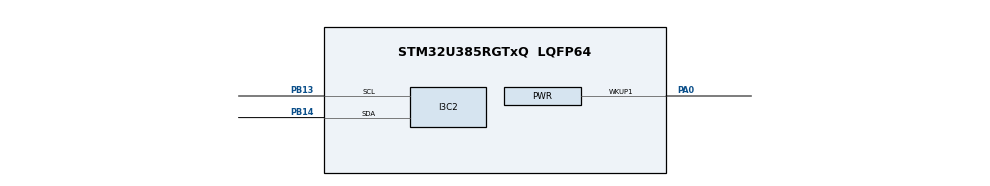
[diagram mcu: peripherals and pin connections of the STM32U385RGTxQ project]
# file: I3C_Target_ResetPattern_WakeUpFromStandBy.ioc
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CORTEX_M33_NS.userName=CORTEX_M33
I3C2.IBIPayloadSize=HAL_I3C_PAYLOAD_EMPTY
I3C2.Identifier=0xC6
I3C2.MIPIIdentifier=DEVICE_ID
I3C2.MaxReadDataSize=0xFF
I3C2.MaxWriteDataSize=0xFF
I3C2.Register1=0x000000f8
I3C2.T_BusAvailableDuration=10000
I3C2.hexBusAvailableDuration=0xf8
Mcu.Family=STM32U3
Mcu.Name=STM32U385RGTxQ
Mcu.Package=LQFP64
Mcu.UserConstants=DEVICE_ID,0x01
NVIC.I3C2_ER_IRQn=true\:0\:0\:false\:false\:true\:true\:true\:true
NVIC.I3C2_EV_IRQn=true\:0\:0\:false\:false\:true\:true\:true\:true
NVIC.PriorityGroup=NVIC_PRIORITYGROUP_4
PA0.Mode=WakeUp1
PA0.Signal=PWR_WKUP1
PB13.Mode=Target
PB13.Signal=I3C2_SCL
PB14.Mode=Target
PB14.Signal=I3C2_SDA
PWR.pwrPrivilege=PWR_PRIVILEGE_NO
ProjectManager.HeapSize=0x200
ProjectManager.StackSize=0x400
ProjectManager.TargetToolchain=EWARM V9.20
RCC.ADCFreq_Value=96000000
RCC.AHBFreq_Value=96000000
RCC.APB1Freq_Value=96000000
RCC.APB1TimFreq_Value=96000000
RCC.APB2Freq_Value=96000000
RCC.APB2TimFreq_Value=96000000
RCC.APB3Freq_Value=96000000
RCC.CortexFreq_Value=12000000
RCC.HCLKFreq_Value=96000000
RCC.HSE_VALUE=16000000
RCC.HSI48_VALUE=48000000
RCC.HSI_VALUE=16000000
RCC.I3C2CLockSelection=RCC_I3C2CLKSOURCE_MSIK
RCC.LSE_VALUE=32768
RCC.LSIDIV_VALUE=32000
RCC.MSISDIV=RCC_MSI_DIV1
RCC.SYSCLKFreq_VALUE=96000000
RCC.USBFreq_Value=96000000
VP_ICACHE_VS_ICACHE.Mode=DirectMappedCache
VP_MEMORYMAP_VS_MEMORYMAP.Mode=CurAppReg
VP_PWR_VS_DBSignals.Mode=DisableDeadBatterySignals
VP_PWR_VS_LPOM.Mode=PowerOptimisation
VP_PWR_VS_SECSignals.Mode=Security/Privilege
board=custom

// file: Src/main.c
/* USER CODE BEGIN Header */
/**
  ******************************************************************************
  * @file           : I3C/I3C_Target_ResetPattern_WakeUpFromStandBy/Src/main.c
  * @brief          : This sample code shows how to use STM32U3xx I3C HAL API
  *                   as Target to detect reset pattern and wake up from Standby mode.
  *                   The communication is done using 2 boards.
  ******************************************************************************
  * @attention
  *
  * Copyright (c) 2024 STMicroelectronics.
  * All rights reserved.
  *
  * This software is licensed under terms that can be found in the LICENSE file
  * in the root directory of this software component.
  * If no LICENSE file comes with this software, it is provided AS-IS.
  *
  ******************************************************************************
  */
/* USER CODE END Header */
#include "main.h"

I3C_HandleTypeDef hi3c2;

/* USER CODE BEGIN PV */
/* Variable used to catch completion of Dynamic address assignment procedure */
__IO uint8_t ubDynamicAddressCplt = 0;

/* Variable used to catch wake up from stand by */
__IO uint8_t ubWakeUpFromStandBy = 0;
/* USER CODE END PV */

void SystemClock_Config(void);
static void MX_GPIO_Init(void);
static void MX_I3C2_Init(void);
static void MX_ICACHE_Init(void);

int main(void)
{

  /* MCU Configuration--------------------------------------------------------*/

  /* Reset of all peripherals, Initializes the Flash interface and the Systick. */
  HAL_Init();

  /* USER CODE BEGIN Init */
  /* Check StandBy flag */
  if (__HAL_PWR_GET_FLAG(PWR_FLAG_SBF) == 1U)
  {
    /* Clear standby flag */
    __HAL_PWR_CLEAR_FLAG(PWR_FLAG_SBF);

    /* Check and clear wake up flag */
    if (HAL_PWR_GetClearWakeupSource() == PWR_WAKEUP_LINE10)
    {
      /* Wake up from STANDBY */
      ubWakeUpFromStandBy = 1U;
    }
    else
    {
      Error_Handler();
    }
  }
  /* USER CODE END Init */

  /* Configure the system clock */
  SystemClock_Config();

  /* Initialize all configured peripherals */
  MX_GPIO_Init();
  MX_I3C2_Init();
  MX_ICACHE_Init();
  /* USER CODE BEGIN 2 */
  /* Configure LD2 */
  BSP_LED_Init(LD2);

  /* Check if target wake up from standby */
  if (ubWakeUpFromStandBy == 1U)
  {
    /* Turn LD2 on: target wake up from standby */
    BSP_LED_On(LD2);
  }
  /*##- Start the listen mode process ####################################*/
  /* Activate notifications for specially for this example
  - Dynamic address association */
  if (HAL_I3C_ActivateNotification(&hi3c2, NULL, HAL_I3C_IT_DAUPDIE) != HAL_OK)
  {
    /* Error_Handler() function is called when error occurs. */
    Error_Handler();
  }

  /*##- Wait for the end of the transfer #################################*/
  /*  Before starting a new communication transfer, you need to check the
  end of current transfer before starting a new one.
  For simplicity reasons, this example is just waiting till the end of the
  transfer, but application may perform other tasks while transfer operation
  is ongoing. */
  while (ubDynamicAddressCplt != 1)
  {
  }

  /* Check if target wake up from standby */
  if (ubWakeUpFromStandBy == 0U)
  {
    /* Enable the wake up line 10 for I3C2 */
    HAL_PWR_EnableWakeUpLine(PWR_WAKEUP_LINE10, PWR_WAKEUP_SELECT_0, PWR_WAKEUP_POLARITY_LOW);

    /* Enable I3C pull-up */
    HAL_PWREx_EnableI3CPullUp(PWR_I3CPU_PB13);
    HAL_PWREx_EnableI3CPullUp(PWR_I3CPU_PB14);

    /* Enable PWR interrupt */
    HAL_NVIC_EnableIRQ(PWR_IRQn);
    HAL_NVIC_SetPriority(PWR_IRQn, 0, 0);

    /* Disable the Debug Module during Standby mode. */
    HAL_DBGMCU_DisableDBGStandbyMode();

    /* Enter in standby mode */
    HAL_PWR_EnterSTANDBYMode();
  }

  /* USER CODE END 2 */

  /* Infinite loop */
  while (1)
  {

  }
}

void SystemClock_Config(void)
{
  RCC_OscInitTypeDef RCC_OscInitStruct = {0};
  RCC_ClkInitTypeDef RCC_ClkInitStruct = {0};

  /** Configure the System Power Supply
  */
  if (HAL_PWREx_ConfigSupply(PWR_SMPS_SUPPLY) != HAL_OK)
  {
    Error_Handler();
  }

  /** Enable Epod Booster
  */
  if (HAL_RCCEx_EpodBoosterClkConfig(RCC_EPODBOOSTER_SOURCE_MSIS, RCC_EPODBOOSTER_DIV1) != HAL_OK)
  {
    Error_Handler();
  }
  if (HAL_PWREx_EnableEpodBooster() != HAL_OK)
  {
    Error_Handler();
  }

  /** Configure the main internal regulator output voltage
  */
  if (HAL_PWREx_ControlVoltageScaling(PWR_REGULATOR_VOLTAGE_SCALE1) != HAL_OK)
  {
    Error_Handler();
  }

  /** Set Flash latency before increasing MSIS
  */
  __HAL_FLASH_SET_LATENCY(FLASH_LATENCY_2);

  /** Initializes the CPU, AHB and APB buses clocks
  */
  RCC_OscInitStruct.OscillatorType = RCC_OSCILLATORTYPE_MSIS|RCC_OSCILLATORTYPE_MSIK;
  RCC_OscInitStruct.MSISState = RCC_MSI_ON;
  RCC_OscInitStruct.MSISSource = RCC_MSI_RC0;
  RCC_OscInitStruct.MSISDiv = RCC_MSI_DIV1;
  RCC_OscInitStruct.MSIKState = RCC_MSI_ON;
  RCC_OscInitStruct.MSIKSource = RCC_MSI_RC0;
  RCC_OscInitStruct.MSIKDiv = RCC_MSI_DIV1;

  if (HAL_RCC_OscConfig(&RCC_OscInitStruct) != HAL_OK)
  {
    Error_Handler();
  }

  /** Initializes the CPU, AHB and APB buses clocks
  */
  RCC_ClkInitStruct.ClockType = RCC_CLOCKTYPE_HCLK|RCC_CLOCKTYPE_SYSCLK
                              |RCC_CLOCKTYPE_PCLK1|RCC_CLOCKTYPE_PCLK2
                              |RCC_CLOCKTYPE_PCLK3;
  RCC_ClkInitStruct.SYSCLKSource = RCC_SYSCLKSOURCE_MSIS;
  RCC_ClkInitStruct.AHBCLKDivider = RCC_SYSCLK_DIV1;
  RCC_ClkInitStruct.APB1CLKDivider = RCC_HCLK_DIV1;
  RCC_ClkInitStruct.APB2CLKDivider = RCC_HCLK_DIV1;
  RCC_ClkInitStruct.APB3CLKDivider = RCC_HCLK_DIV1;

  if (HAL_RCC_ClockConfig(&RCC_ClkInitStruct, FLASH_LATENCY_2) != HAL_OK)
  {
    Error_Handler();
  }
}

static void MX_I3C2_Init(void)
{

  I3C_FifoConfTypeDef sFifoConfig = {0};
  I3C_TgtConfTypeDef sTgtConfig = {0};

  hi3c2.Instance = I3C2;
  hi3c2.Mode = HAL_I3C_MODE_TARGET;
  hi3c2.Init.TgtBusCharacteristic.BusAvailableDuration = 0xf8;
  if (HAL_I3C_Init(&hi3c2) != HAL_OK)
  {
    Error_Handler();
  }

  /** Configure FIFO
  */
  sFifoConfig.RxFifoThreshold = HAL_I3C_RXFIFO_THRESHOLD_1_4;
  sFifoConfig.TxFifoThreshold = HAL_I3C_TXFIFO_THRESHOLD_1_4;
  sFifoConfig.ControlFifo = HAL_I3C_CONTROLFIFO_DISABLE;
  sFifoConfig.StatusFifo = HAL_I3C_STATUSFIFO_DISABLE;

  if (HAL_I3C_SetConfigFifo(&hi3c2, &sFifoConfig) != HAL_OK)
  {
    Error_Handler();
  }

  /** Configure Target
  */
  sTgtConfig.Identifier = 0xC6;
  sTgtConfig.MIPIIdentifier = DEVICE_ID;
  sTgtConfig.CtrlRoleRequest = DISABLE;
  sTgtConfig.HotJoinRequest = DISABLE;
  sTgtConfig.IBIRequest = DISABLE;
  sTgtConfig.IBIPayload = DISABLE;
  sTgtConfig.IBIPayloadSize = HAL_I3C_PAYLOAD_EMPTY;
  sTgtConfig.MaxReadDataSize = 0xFF;
  sTgtConfig.MaxWriteDataSize = 0xFF;
  sTgtConfig.CtrlCapability = DISABLE;
  sTgtConfig.GroupAddrCapability = DISABLE;
  sTgtConfig.DataTurnAroundDuration = HAL_I3C_TURNAROUND_TIME_TSCO_LESS_12NS;
  sTgtConfig.MaxReadTurnAround = 0;
  sTgtConfig.MaxDataSpeed = HAL_I3C_GETMXDS_FORMAT_1;
  sTgtConfig.MaxSpeedLimitation = DISABLE;
  sTgtConfig.HandOffActivityState = HAL_I3C_HANDOFF_ACTIVITY_STATE_0;
  sTgtConfig.HandOffDelay = DISABLE;
  sTgtConfig.PendingReadMDB = DISABLE;
  if (HAL_I3C_Tgt_Config(&hi3c2, &sTgtConfig) != HAL_OK)
  {
    Error_Handler();
  }

}

static void MX_ICACHE_Init(void)
{

  /** Enable instruction cache in 1-way (direct mapped cache)
  */
  if (HAL_ICACHE_ConfigAssociativityMode(ICACHE_1WAY) != HAL_OK)
  {
    Error_Handler();
  }
  if (HAL_ICACHE_Enable() != HAL_OK)
  {
    Error_Handler();
  }

}

static void MX_GPIO_Init(void)
{

  /* GPIO Ports Clock Enable */
  __HAL_RCC_GPIOA_CLK_ENABLE();
  __HAL_RCC_GPIOB_CLK_ENABLE();

}

/* USER CODE BEGIN 4 */
/**
  * @brief I3C notify callback after receiving a notification.
  *        The main objective of this user function is to check on the notification ID and assign 1 to the global
  *        variable used to indicate that the event is well finished.
  * @par Called functions
  * - HAL_I3C_NotifyCallback()
  * @retval None
  */
void HAL_I3C_NotifyCallback(I3C_HandleTypeDef *hi3c, uint32_t eventId)
{
  if ((eventId & EVENT_ID_DAU) == EVENT_ID_DAU)
  {
    ubDynamicAddressCplt = 1;
  }
  else
  {
    /* Error_Handler() function is called when error occurs. */
    Error_Handler();
  }
}

/**
  * @brief PWR WKUP10 interrupt callback.
  * @retval None.
  */
void HAL_PWR_WKUP10_Callback(void)
{
  /* Turn LD2 on: target wake up from Stop mode */
  BSP_LED_On(LD2);
}
/* USER CODE END 4 */

void Error_Handler(void)
{
  /* USER CODE BEGIN Error_Handler_Debug */
  /* User can add his own implementation to report the HAL error return state */
  while (1)
  {
    BSP_LED_Toggle(LD2);
    HAL_Delay(1000);
  }
  /* USER CODE END Error_Handler_Debug */
}
